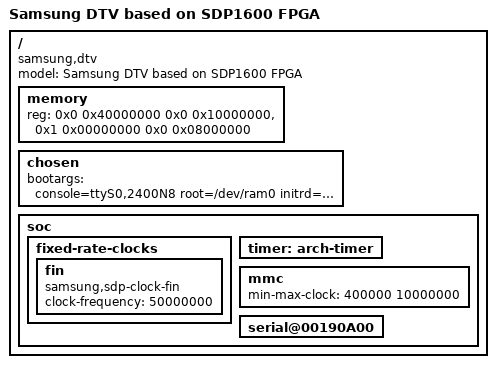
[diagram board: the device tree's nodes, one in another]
/*
 * Copyright (C) 2014 Samsung Electronics Co.Ltd
 *
 * This program is free software; you can redistribute it and/or modify
 * it under the terms of the GNU General Public License version 2 as
 * published by the Free Software Foundation.
 */

/dts-v1/;

#include "sdp1600.dtsi"

/ {
	model = "Samsung DTV based on SDP1600 FPGA";
	compatible = "samsung,dtv", "samsung,sdp1600";

	memory {
		device_type = "memory";
//		reg = <0x0 0x40000000 0x0 0x10000000>;
//		reg = <0x1 0x00000000 0x0 0x10000000>;
		reg = <0x0 0x40000000 0x0 0x10000000>, 
			<0x1 0x00000000 0x0 0x08000000>;

	};
	chosen {
		bootargs = "console=ttyS0,2400N8 root=/dev/ram0 initrd=0x42000000,32M rootwait earlyprintk fpga debug user_debug=31";
//		bootargs = "console=hvc0,9600N8 root=/dev/ram0 initrd=0x42000000,32M rootwait earlyprintk fpga debug nosmp user_debug=31";
	};

	soc	{
		fixed-rate-clocks {
			fin {
				compatible = "samsung,sdp-clock-fin";
				clock-frequency = <50000000>;//PLL3
			};
		};

		timer: arch-timer {
			//clock-frequency = <3000000>;
		};

		mmc {
			status = "okay";
			min-max-clock = <400000 10000000>;
		};

		serial@00190A00 {
			status = "okay";
		};
	};
};

